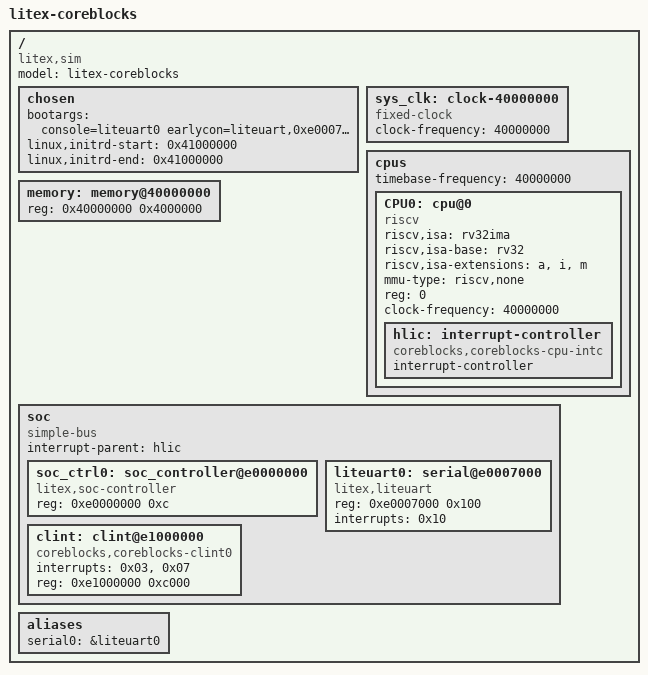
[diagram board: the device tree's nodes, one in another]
/dts-v1/;

/ {
    compatible = "litex,sim", "litex,soc";
    model = "litex-coreblocks";
    #address-cells = <1>;
    #size-cells    = <1>;

    chosen {
        //bootargs = "console=devLXU0,115200 earlycon=liteuart,0xe0007000 rootwait root=/dev/ram0";
        bootargs = "console=liteuart0 earlycon=liteuart,0xe0007000 rootwait root=/dev/ram0";
        linux,initrd-start = <0x41000000>; // NOTE: update in post-image.sh if changed
        linux,initrd-end   = <0x41000000>; // relpaced by post-image.sh to real initrd size
    };
    
    sys_clk: clock-40000000 {
        compatible = "fixed-clock";
        #clock-cells = <0>;
        clock-frequency  = <40000000>;
    };

	cpus {
        #address-cells = <1>;
        #size-cells    = <0>;
        timebase-frequency = <40000000>;

        CPU0: cpu@0 {
            device_type = "cpu";
            compatible = "riscv";
            riscv,isa = "rv32ima";
            riscv,isa-base = "rv32";
            riscv,isa-extensions = "a", "i", "m";
            mmu-type = "riscv,none";
            reg = <0>;
            clock-frequency = <40000000>;
            status = "okay";

			hlic: interrupt-controller {
				#interrupt-cells = <1>;
				compatible = "coreblocks,coreblocks-cpu-intc", "riscv,cpu-intc";
				interrupt-controller;
			};
		};
	};

    memory: memory@40000000 {
        device_type = "memory";
        reg = <0x40000000 0x4000000>;
    };

    soc {
        #address-cells = <1>;
        #size-cells    = <1>;
        compatible = "simple-bus";
        interrupt-parent = <&hlic>;
        ranges;

        soc_ctrl0: soc_controller@e0000000 {
            compatible = "litex,soc-controller";
            reg = <0xe0000000 0xc>;
            status = "okay";
        };

        liteuart0: serial@e0007000 {
            compatible = "litex,liteuart";
            reg = <0xe0007000 0x100>;
            interrupts = <0x10>;
            status = "okay";
        };
/*
        liteuart1: serial@e0007800 {
            //compatible = "litex,liteuart-experimental";
            compatible = "litex,liteuart";
            reg = <0xe0007800 0x100>;
            interrupts = <0x18>;
            status = "okay";
        }; */

        
        clint: clint@e1000000 {
			interrupts = <0x03>, <0x07>;
			reg = <0xe1000000 0xc000>;
		    compatible = "coreblocks,coreblocks-clint0", "sifive,clint0";
		};
    };

    aliases {
        serial0 = &liteuart0;
    };
};
